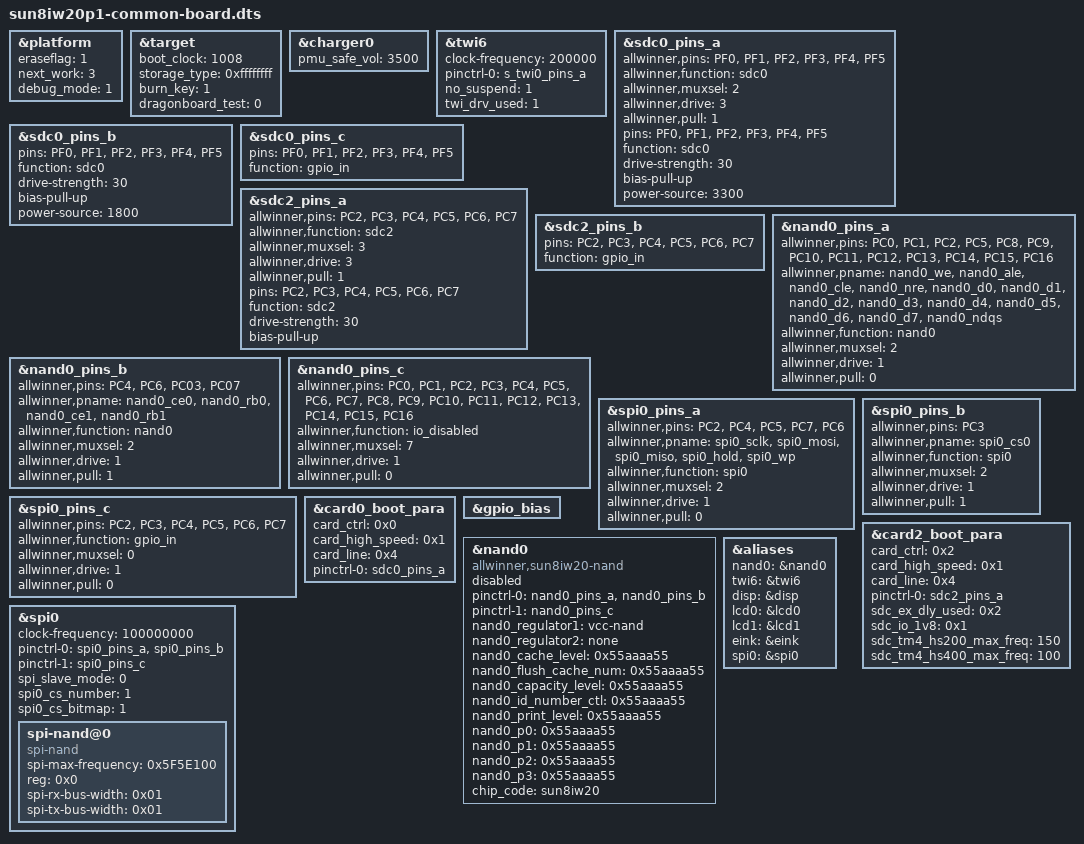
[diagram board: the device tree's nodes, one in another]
/*
 * Allwinner Technology CO., Ltd. sun8iw20p1 soc board.
 *
 * soc board support.
 */

&platform {
	eraseflag   = <1>;
	next_work   = <3>;
	debug_mode  = <1>;
};

&target {
	boot_clock = <1008>;	/*CPU boot frequency, Unit: MHz*/
	storage_type = <0xffffffff>; /*boot medium, 0-nand, 1-card0, 2-card2, -1(defualt)auto scan*/
	burn_key = <1>;		/*1:support burn key; 0:not support burn key*/
	dragonboard_test = <0>;	/*1:support card boot dragonboard; 0:not support card boot dragonboard*/
};


&charger0 {
	pmu_safe_vol = <3500>;
};


&twi6 {
	clock-frequency = <200000>;
	pinctrl-0 = <&s_twi0_pins_a>;
	no_suspend = <1>;
	twi_drv_used = <1>;
	status = "okay";
};

&sdc0_pins_a {
	allwinner,pins = "PF0", "PF1", "PF2",
			 "PF3", "PF4", "PF5";
	allwinner,function = "sdc0";
	allwinner,muxsel = <2>;
	allwinner,drive = <3>;
	allwinner,pull = <1>;
	pins = "PF0", "PF1", "PF2",
	       "PF3", "PF4", "PF5";
	function = "sdc0";
	drive-strength = <30>;
	bias-pull-up;
	power-source = <3300>;
};

&sdc0_pins_b {
	pins = "PF0", "PF1", "PF2",
	       "PF3", "PF4", "PF5";
	function = "sdc0";
	drive-strength = <30>;
	bias-pull-up;
	power-source = <1800>;
};

&sdc0_pins_c {
		pins = "PF0", "PF1", "PF2",
			"PF3", "PF4", "PF5";
		function = "gpio_in";

};


&sdc2_pins_a {
	allwinner,pins = "PC2", "PC3", "PC4",
			 "PC5", "PC6", "PC7";
	allwinner,function = "sdc2";
	allwinner,muxsel = <3>;
	allwinner,drive = <3>;
	allwinner,pull = <1>;
	pins = "PC2", "PC3", "PC4",
		"PC5", "PC6", "PC7";
	function = "sdc2";
	drive-strength = <30>;
	bias-pull-up;

};

&sdc2_pins_b {
	pins = "PC2", "PC3", "PC4",
	       "PC5", "PC6", "PC7";
	function = "gpio_in";
};



&nand0_pins_a {
	allwinner,pins = "PC0", "PC1", "PC2", "PC5",
			 "PC8", "PC9", "PC10", "PC11",
			 "PC12", "PC13", "PC14", "PC15",
			 "PC16";
	allwinner,pname= "nand0_we", "nand0_ale","nand0_cle", "nand0_nre",
			 "nand0_d0", "nand0_d1", "nand0_d2", "nand0_d3",
			 "nand0_d4", "nand0_d5", "nand0_d6", "nand0_d7",
			 "nand0_ndqs";
	allwinner,function = "nand0";
	allwinner,muxsel = <2>;
	allwinner,drive = <1>;
	allwinner,pull = <0>;
};

&nand0_pins_b {
	allwinner,pins = "PC4", "PC6", "PC03", "PC07";
	allwinner,pname= "nand0_ce0", "nand0_rb0", "nand0_ce1", "nand0_rb1";
	allwinner,function = "nand0";
	allwinner,muxsel = <2>;
	allwinner,drive = <1>;
	allwinner,pull = <1>;	/* only RB&CE should be pulled up */
};

&nand0_pins_c {
	allwinner,pins = "PC0", "PC1", "PC2", "PC3",
			 "PC4", "PC5", "PC6", "PC7",
			 "PC8", "PC9", "PC10", "PC11",
			 "PC12", "PC13", "PC14", "PC15",
			 "PC16";
	allwinner,function = "io_disabled";
	allwinner,muxsel = <7>;
	allwinner,drive = <1>;
	allwinner,pull = <0>;
};

&spi0_pins_a {
	allwinner,pins = "PC2", "PC4", "PC5",
			"PC7", "PC6";
	allwinner,pname = "spi0_sclk", "spi0_mosi",
			"spi0_miso", "spi0_hold", "spi0_wp";
	allwinner,function = "spi0";
	allwinner,muxsel = <2>;
	allwinner,drive = <1>;
	allwinner,pull = <0>;
};

&spi0_pins_b {
	allwinner,pins = "PC3";
	allwinner,pname = "spi0_cs0";
	allwinner,function = "spi0";
	allwinner,muxsel = <2>;
	allwinner,drive = <1>;
	allwinner,pull = <1>;   // only CS should be pulled up
};

&spi0_pins_c {
	allwinner,pins = "PC2", "PC3", "PC4", "PC5",
			"PC6", "PC7";
	allwinner,function = "gpio_in";
	allwinner,muxsel = <0>;
	allwinner,drive = <1>;
	allwinner,pull = <0>;
};

&card0_boot_para {  /* Avoid dtc compiling warnings. @TODO: Developer should modify this to the actual value */
	/* reg = <0x0 0x2 0x0 0x0>;  [> Avoid dtc compiling warnings. @TODO: Developer should modify this to the actual value <] */
	device_type = "card0_boot_para";
	card_ctrl = <0x0>;
	card_high_speed = <0x1>;
	card_line = <0x4>;
	pinctrl-0 = <&sdc0_pins_a>;
};

&card2_boot_para {  /* Avoid dtc compiling warnings. @TODO: Developer should modify this to the actual value */
	/* reg = <0x0 0x3 0x0 0x0>;  [> Avoid dtc compiling warnings. @TODO: Developer should modify this to the actual value <] */
	device_type = "card2_boot_para";
	card_ctrl = <0x2>;
	card_high_speed = <0x1>;
	card_line = <0x4>;
	pinctrl-0 = <&sdc2_pins_a>;
	sdc_ex_dly_used = <0x2>;
	sdc_io_1v8 = <0x1>;
	sdc_tm4_hs200_max_freq = <150>;
	sdc_tm4_hs400_max_freq = <100>;
};
&gpio_bias {  /* Avoid dtc compiling warnings. @TODO: Developer should modify this to the actual value */
	device_type = "gpio_bias";
};

&nand0 {
	compatible = "allwinner,sun8iw20-nand";
	device_type = "nand0";
	//reg = <0x0 0x04011000 0x0 0x1000>;/* nand0 */
	pinctrl-names = "default", "sleep";
	pinctrl-0 = <&nand0_pins_a &nand0_pins_b>;
	pinctrl-1 = <&nand0_pins_c>;
	nand0_regulator1 = "vcc-nand";
	nand0_regulator2 = "none";
	nand0_cache_level = <0x55aaaa55>;
	nand0_flush_cache_num = <0x55aaaa55>;
	nand0_capacity_level = <0x55aaaa55>;
	nand0_id_number_ctl = <0x55aaaa55>;
	nand0_print_level = <0x55aaaa55>;
	nand0_p0 = <0x55aaaa55>;
	nand0_p1 = <0x55aaaa55>;
	nand0_p2 = <0x55aaaa55>;
	nand0_p3 = <0x55aaaa55>;
	chip_code = "sun8iw20";
	status = "disabled";
};

&spi0 {
	clock-frequency = <100000000>;
	pinctrl-0 = <&spi0_pins_a &spi0_pins_b>;
	pinctrl-1 = <&spi0_pins_c>;
	pinctrl-names = "default", "sleep";
	/*spi-supply = <&reg_dcdc1>;*/
	spi_slave_mode = <0>;
	spi0_cs_number = <1>;
	spi0_cs_bitmap = <1>;
	status = "okay";

	spi-nand@0 {
		compatible = "spi-nand";
		spi-max-frequency=<0x5F5E100>;
		reg = <0x0>;
		spi-rx-bus-width=<0x01>;
		spi-tx-bus-width=<0x01>;
		status="okay";
	};
};

&aliases {
	nand0 = &nand0;
	twi6 = &twi6;
	disp = &disp;
	lcd0 = &lcd0;
	lcd1 = &lcd1;
	eink = &eink;
	spi0 = &spi0;

};
